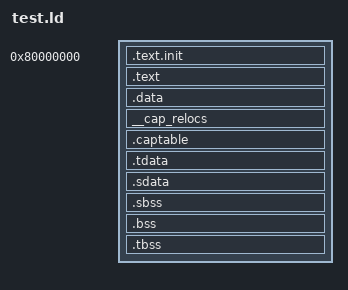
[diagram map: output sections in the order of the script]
/*======================================================================*/
/* Proxy kernel linker script                                           */
/*======================================================================*/
/* This is the linker script used when building the proxy kernel. */

/*----------------------------------------------------------------------*/
/* Setup                                                                */
/*----------------------------------------------------------------------*/

/* The OUTPUT_ARCH command specifies the machine architecture where the
   argument is one of the names used in the BFD library. More
   specifically one of the entires in bfd/cpu-mips.c */

OUTPUT_ARCH( "riscv" )
ENTRY(_start)

/*----------------------------------------------------------------------*/
/* Sections                                                             */
/*----------------------------------------------------------------------*/

SECTIONS
{

  /* text: test code section */
  . = 0x80000000;
  .text.init : { *(.text.init) }

  .text : { *(.text) }

  /* data segment */
  .data : ALIGN(8) { *(.data) }

  __cap_relocs : {
     . = ALIGN(8);
  }

  .captable : {
     . = ALIGN(8);
  }

  /* thread-local data segment */
  .tdata :
  {
    _tls_data = .;
    *(.tdata.begin)
    *(.tdata)
    *(.tdata.end)
  }

  .sdata : {
    __global_pointer$ = . + 0x800;
    *(.srodata.cst16) *(.srodata.cst8) *(.srodata.cst4) *(.srodata.cst2) *(.srodata*)
    *(.sdata .sdata.* .gnu.linkonce.s.*)
  }

  /* bss segment */
  .sbss : {
   . = ALIGN(8);
    __sbss_start = .;
    *(.sbss .sbss.* .gnu.linkonce.sb.*)
    *(.scommon)
   . = ALIGN(8);
    __sbss_end = .;
  }

  .bss : {
    . = ALIGN(8);
    __bss_start = .;
    *(.bss)
    . = ALIGN(8);
    __bss_end = .;
  }

  .tbss :
  {
    . = ALIGN(8);
    *(.tbss)
    *(.tbss.end)
  }

  /* End of uninitalized data segement */
  _end = .;
}

